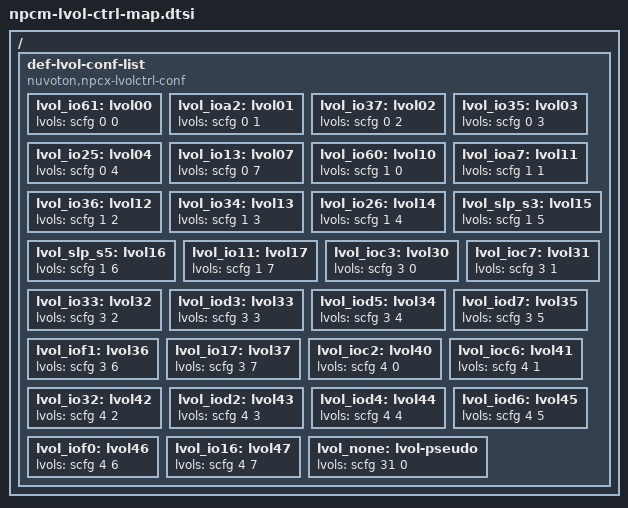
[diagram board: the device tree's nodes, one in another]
/*
 * Copyright (c) 2024 Nuvoton Technology Corporation.
 *
 * SPDX-License-Identifier: Apache-2.0
 */

/ {
	def-lvol-conf-list {
		compatible = "nuvoton,npcx-lvolctrl-conf";

		/* Low-Voltage IO Control 0 */
		lvol_io61: lvol00 {
			lvols = <&scfg 0 0>;
		};

		lvol_ioa2: lvol01 {
			lvols = <&scfg 0 1>;
		};

		lvol_io37: lvol02 {
			lvols = <&scfg 0 2>;
		};

		lvol_io35: lvol03 {
			lvols = <&scfg 0 3>;
		};

		lvol_io25: lvol04 {
			lvols = <&scfg 0 4>;
		};

		lvol_io13: lvol07 {
			lvols = <&scfg 0 7>;
		};

		/* Low-Voltage IO Control 1 */
		lvol_io60: lvol10 {
			lvols = <&scfg 1 0>;
		};

		lvol_ioa7: lvol11 {
			lvols = <&scfg 1 1>;
		};

		lvol_io36: lvol12 {
			lvols = <&scfg 1 2>;
		};

		lvol_io34: lvol13 {
			lvols = <&scfg 1 3>;
		};

		lvol_io26: lvol14 {
			lvols = <&scfg 1 4>;
		};

		lvol_slp_s3: lvol15 {
			lvols = <&scfg 1 5>;
		};

		lvol_slp_s5: lvol16 {
			lvols = <&scfg 1 6>;
		};

		lvol_io11: lvol17 {
			lvols = <&scfg 1 7>;
		};

		/* Low-Voltage IO Control 3 */
		lvol_ioc3: lvol30 {
			lvols = <&scfg 3 0>;
		};

		lvol_ioc7: lvol31 {
			lvols = <&scfg 3 1>;
		};

		lvol_io33: lvol32 {
			lvols = <&scfg 3 2>;
		};

		lvol_iod3: lvol33 {
			lvols = <&scfg 3 3>;
		};

		lvol_iod5: lvol34 {
			lvols = <&scfg 3 4>;
		};

		lvol_iod7: lvol35 {
			lvols = <&scfg 3 5>;
		};

		lvol_iof1: lvol36 {
			lvols = <&scfg 3 6>;
		};

		lvol_io17: lvol37 {
			lvols = <&scfg 3 7>;
		};

		/* Low-Voltage IO Control 4 */
		lvol_ioc2: lvol40 {
			lvols = <&scfg 4 0>;
		};

		lvol_ioc6: lvol41 {
			lvols = <&scfg 4 1>;
		};

		lvol_io32: lvol42 {
			lvols = <&scfg 4 2>;
		};

		lvol_iod2: lvol43 {
			lvols = <&scfg 4 3>;
		};

		lvol_iod4: lvol44 {
			lvols = <&scfg 4 4>;
		};

		lvol_iod6: lvol45 {
			lvols = <&scfg 4 5>;
		};

		lvol_iof0: lvol46 {
			lvols = <&scfg 4 6>;
		};

		lvol_io16: lvol47 {
			lvols = <&scfg 4 7>;
		};

		lvol_none: lvol-pseudo {
			lvols = <&scfg 31 0>;
		};
	};
};
